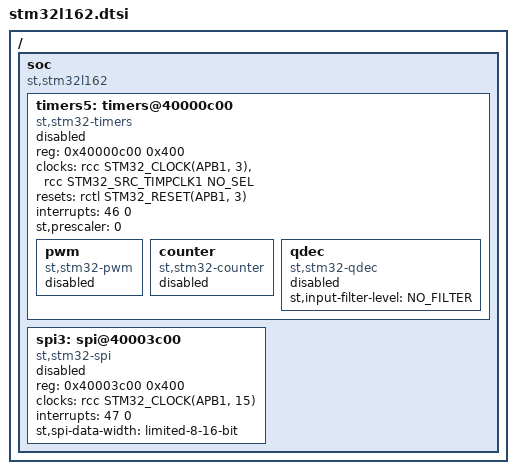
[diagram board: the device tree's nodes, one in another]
/*
 * Copyright (c) 2026 Filip Stojanovic <filipembedded@gmail.com>
 *
 * SPDX-License-Identifier: Apache-2.0
 */

#include <st/l1/stm32l152.dtsi>

/ {
	soc {
		compatible = "st,stm32l162", "st,stm32l1", "simple-bus";

		timers5: timers@40000c00 {
			compatible = "st,stm32-timers";
			reg = <0x40000c00 0x400>;
			clocks = <&rcc STM32_CLOCK(APB1, 3)>,
				 <&rcc STM32_SRC_TIMPCLK1 NO_SEL>;
			resets = <&rctl STM32_RESET(APB1, 3)>;
			interrupts = <46 0>;
			interrupt-names = "global";
			st,prescaler = <0>;
			status = "disabled";

			pwm {
				compatible = "st,stm32-pwm";
				#pwm-cells = <3>;
				status = "disabled";
			};

			counter {
				compatible = "st,stm32-counter";
				status = "disabled";
			};

			qdec {
				compatible = "st,stm32-qdec";
				st,input-filter-level = <NO_FILTER>;
				status = "disabled";
			};
		};

		spi3: spi@40003c00 {
			compatible = "st,stm32-spi";
			reg = <0x40003c00 0x400>;
			#address-cells = <1>;
			#size-cells = <0>;
			clocks = <&rcc STM32_CLOCK(APB1, 15)>;
			interrupts = <47 0>;
			st,spi-data-width = "limited-8-16-bit";
			status = "disabled";
		};
	};
};
